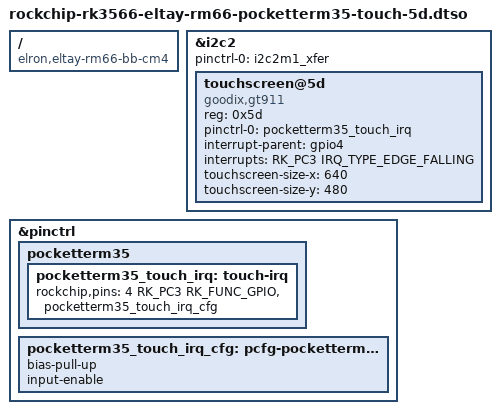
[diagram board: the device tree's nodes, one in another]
// SPDX-License-Identifier: GPL-2.0
/dts-v1/;
/plugin/;

#include <dt-bindings/interrupt-controller/irq.h>
#include <dt-bindings/pinctrl/rockchip.h>

/ {
	compatible = "elron,eltay-rm66-bb-cm4", "rockchip,rk3566";

	fragment@0 {
		target = <&i2c2>;

		__overlay__ {
			#address-cells = <1>;
			#size-cells = <0>;
			pinctrl-names = "default";
			pinctrl-0 = <&i2c2m1_xfer>;
			status = "okay";

			touchscreen@5d {
				compatible = "goodix,gt911";
				reg = <0x5d>;
				pinctrl-names = "default";
				pinctrl-0 = <&pocketterm35_touch_irq>;
				interrupt-parent = <&gpio4>;
				interrupts = <RK_PC3 IRQ_TYPE_EDGE_FALLING>;
				touchscreen-size-x = <640>;
				touchscreen-size-y = <480>;
			};
		};
	};

	fragment@1 {
		target = <&pinctrl>;

		__overlay__ {
			pocketterm35 {
				pocketterm35_touch_irq: touch-irq {
					rockchip,pins =
						<4 RK_PC3 RK_FUNC_GPIO &pocketterm35_touch_irq_cfg>;
				};
			};

			pocketterm35_touch_irq_cfg: pcfg-pocketterm35-touch-irq {
				bias-pull-up;
				input-enable;
			};
		};
	};
};
